# CPU_ETM register map
Vendor: Texas Instruments
Peripheral module from a debugger description file (folder CC26x4).
Registers are 32-bit, access per field, reset 0x0 unless marked. A register's access mark holds for its fields unless they carry their own. Offsets are as the file gives them; lines under a group give offsets from that group; [hi:lo] are bit positions; {n}, {i} and the like mark numbered series; 'fields as' and 'values as' point back to an identical list; <NAME> marks a mode.

## CPU_ETM
0x04 TRCPRGCTLR — Programming Control Register
  [0] EN rw — Trace Unit Enable
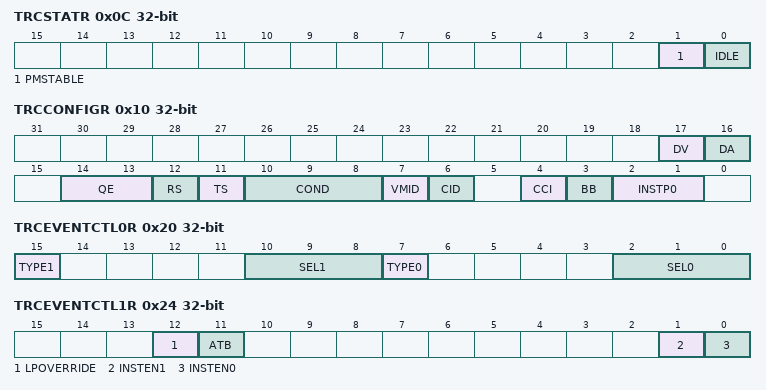
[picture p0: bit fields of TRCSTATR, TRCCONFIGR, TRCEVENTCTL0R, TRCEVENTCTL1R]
0x0C TRCSTATR ro — The TRCSTATR indicates the ETM-Teal status
  [1] PMSTABLE — Indicates whether the ETM-Teal registers are stable and can be read
  [0] IDLE — Indicates that the trace unit is inactive
0x10 TRCCONFIGR ro — The TRCCONFIGR sets the basic tracing options for the trace unit
  [17] DV — Reserved, `ImpDefRES0
  [16] DA — Reserved, `ImpDefRES0
  [14:13] QE — Reserved, `ImpDefRES0
  [12] RS — Reserved, `ImpDefRES0
  [11] TS — Reserved, `ImpDefRES0
  [10:8] COND — Reserved, `ImpDefRES0
  [7] VMID — Reserved, `ImpDefRES0
  [6] CID — Reserved, `ImpDefRES0
  [4] CCI — Reserved, `ImpDefRES0
  [3] BB — Reserved, `ImpDefRES0
  [2:1] INSTP0 — Reserved, `ImpDefRES0
0x20 TRCEVENTCTL0R — The TRCEVENTCTL0R controls the tracing of events in the trace stream. The events also drive the ETM-Teal external outputs.
  [15] TYPE1 rw — Selects the resource type for event 1
  [10:8] SEL1 rw — Selects the resource number, based on the value of TYPE1: When TYPE1 is 0, selects a single selected resource from 0-15 defined by SEL1[2:0]. When TYPE1 is 1, selects a Boolean combined resource pair from 0-7 defined by SEL1[2:0]
  [7] TYPE0 rw — Selects the resource type for event 0
  [2:0] SEL0 rw — Selects the resource number, based on the value of TYPE0: When TYPE1 is 0, selects a single selected resource from 0-15 defined by SEL0[2:0]. When TYPE1 is 1, selects a Boolean combined resource pair from 0-7 defined by SEL0[2:0]
0x24 TRCEVENTCTL1R — The TRCEVENTCTL1R controls how the events selected by TRCEVENTCTL0R behave
  [12] LPOVERRIDE rw — Low power state behavior override
  [11] ATB rw — ATB enabled
  [1] INSTEN1 rw — One bit per event, to enable generation of an event element in the instruction trace stream when the selected event occurs
  [0] INSTEN0 rw — One bit per event, to enable generation of an event element in the instruction trace stream when the selected event occurs
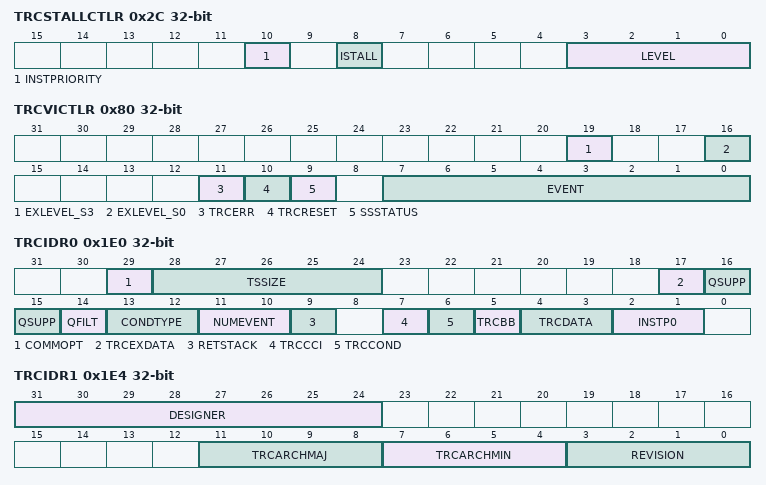
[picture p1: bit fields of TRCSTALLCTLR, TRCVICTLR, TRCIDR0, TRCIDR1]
0x2C TRCSTALLCTLR — The TRCSTALLCTLR enables ETM-Teal to stall the processor if the ETM-Teal FIFO goes over the programmed level to minimize risk of overflow
  [10] INSTPRIORITY rw — Prioritize instruction trace if instruction trace buffer space is less than LEVEL
  [8] ISTALL rw — Stall processor based on instruction trace buffer space
  [3:0] LEVEL rw — Threshold at which stalling becomes active. This provides four levels. This level can be varied to optimize the level of invasion caused by stalling, balanced against the risk of a FIFO overflow
0x30 TRCTSCTLR — The TRCTSCTLR controls the insertion of global timestamps into the trace stream. A timestamp is always inserted into the instruction trace stream
  [7:0] EVENT rw — An event selector. When the selected event is triggered, the trace unit inserts a global timestamp into the trace streams
0x34 TRCSYNCPR ro — The TRCSYNCPR specifies the period of trace synchronization of the trace streams. TRCSYNCPR defines a number of bytes of trace between requests for trace synchronization. This value is always a power of two
  [4:0] PERIOD — Defines the number of bytes of trace between trace synchronization requests as a total of the number of bytes generated by the instruction stream. The number of bytes is 2N where N is the value of this field: - A value of zero disables these periodic trace synchronization requests, but does not disable other trace synchronization requests. - The minimum value that can be programmed, other than zero, is 8, providing a minimum trace synchronization period of 256 bytes. - The maximum value is 20, providing a maximum trace synchronization period of 2^20 bytes
0x38 TRCCCCTLR — The TRCCCCTLR sets the threshold value for instruction trace cycle counting. The threshold represents the minimum interval between cycle count trace packets
  [11:0] THRESHOLD rw — Instruction trace cycle count threshold
0x80 TRCVICTLR — The TRCVICTLR controls instruction trace filtering
  [19] EXLEVEL_S3 rw — In Secure state, each bit controls whether instruction tracing is enabled for the corresponding exception level
  [16] EXLEVEL_S0 rw — In Secure state, each bit controls whether instruction tracing is enabled for the corresponding exception level
  [11] TRCERR rw — Selects whether a system error exception must always be traced
  [10] TRCRESET rw — Selects whether a reset exception must always be traced
  [9] SSSTATUS rw — Indicates the current status of the start/stop logic
  [7:0] EVENT rw — An event selector
{0x140+4i} TRCCNTRLDVR{i} (i=0..2) — The TRCCNTRLDVR defines the reload value for the reduced function counter
  [15:0] VALUE rw — Defines the reload value for the counter. This value is loaded into the counter each time the reload event occurs
0x180 TRCIDR8 ro
  [31:0] MAXSPEC — reads as `ImpDef
0x184 TRCIDR9 ro
  [31:0] NUMP0KEY — reads as `ImpDef
0x188 TRCIDR10 ro
  [31:0] NUMP1KEY — reads as `ImpDef
0x18C TRCIDR11 ro
  [31:0] NUMP1SPC — reads as `ImpDef
0x190 TRCIDR12 ro
  [31:0] NUMCONDKEY — reads as `ImpDef
0x194 TRCIDR13 ro
  [31:0] NUMCONDSPC — reads as `ImpDef
{0x1C0+4i} TRCIMSPEC{i} (i=0..6) — The TRCIMSPEC shows the presence of any IMPLEMENTATION SPECIFIC features, and enables any features that are provided
  [3:0] SUPPORT rw — Set to 0. No IMPLEMENTATION SPECIFIC extensions are supported
0x1E0 TRCIDR0 ro
  [29] COMMOPT — reads as `ImpDef
  [28:24] TSSIZE — reads as `ImpDef
  [17] TRCEXDATA — reads as `ImpDef
  [16:15] QSUPP — reads as `ImpDef
  [14] QFILT — reads as `ImpDef
  [13:12] CONDTYPE — reads as `ImpDef
  [11:10] NUMEVENT — reads as `ImpDef
  [9] RETSTACK — reads as `ImpDef
  [7] TRCCCI — reads as `ImpDef
  [6] TRCCOND — reads as `ImpDef
  [5] TRCBB — reads as `ImpDef
  [4:3] TRCDATA — reads as `ImpDef
  [2:1] INSTP0 — reads as `ImpDef
0x1E4 TRCIDR1 ro
  [31:24] DESIGNER — reads as `ImpDef
  [11:8] TRCARCHMAJ — reads as 0b0100
  [7:4] TRCARCHMIN — reads as 0b0000
  [3:0] REVISION — reads as `ImpDef
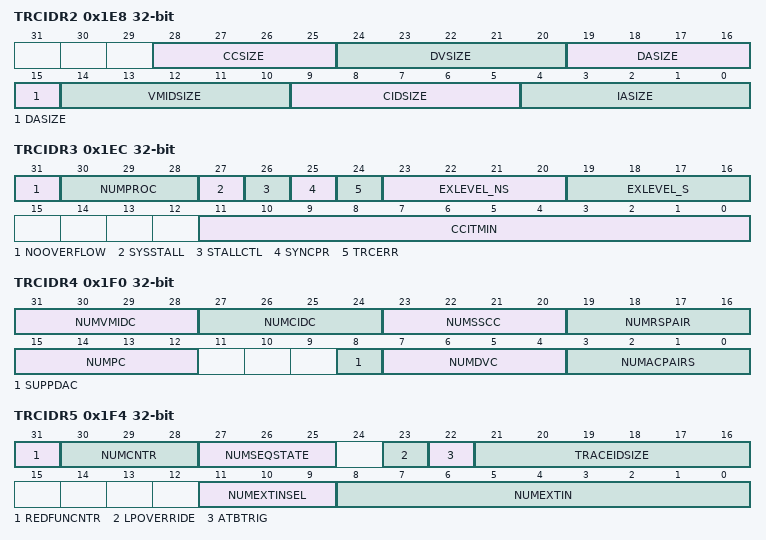
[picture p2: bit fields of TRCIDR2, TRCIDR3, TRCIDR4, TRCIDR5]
0x1E8 TRCIDR2 ro
  [28:25] CCSIZE — reads as `ImpDef
  [24:20] DVSIZE — reads as `ImpDef
  [19:15] DASIZE — reads as `ImpDef
  [14:10] VMIDSIZE — reads as `ImpDef
  [9:5] CIDSIZE — reads as `ImpDef
  [4:0] IASIZE — reads as `ImpDef
0x1EC TRCIDR3 ro
  [31] NOOVERFLOW — reads as `ImpDef
  [30:28] NUMPROC — reads as `ImpDef
  [27] SYSSTALL — reads as `ImpDef
  [26] STALLCTL — reads as `ImpDef
  [25] SYNCPR — reads as `ImpDef
  [24] TRCERR — reads as `ImpDef
  [23:20] EXLEVEL_NS — reads as `ImpDef
  [19:16] EXLEVEL_S — reads as `ImpDef
  [11:0] CCITMIN — reads as `ImpDef
0x1F0 TRCIDR4 ro
  [31:28] NUMVMIDC — reads as `ImpDef
  [27:24] NUMCIDC — reads as `ImpDef
  [23:20] NUMSSCC — reads as `ImpDef
  [19:16] NUMRSPAIR — reads as `ImpDef
  [15:12] NUMPC — reads as `ImpDef
  [8] SUPPDAC — reads as `ImpDef
  [7:4] NUMDVC — reads as `ImpDef
  [3:0] NUMACPAIRS — reads as `ImpDef
0x1F4 TRCIDR5 ro
  [31] REDFUNCNTR — reads as `ImpDef
  [30:28] NUMCNTR — reads as `ImpDef
  [27:25] NUMSEQSTATE — reads as `ImpDef
  [23] LPOVERRIDE — reads as `ImpDef
  [22] ATBTRIG — reads as `ImpDef
  [21:16] TRACEIDSIZE — reads as 0x07
  [11:9] NUMEXTINSEL — reads as `ImpDef
  [8:0] NUMEXTIN — reads as `ImpDef
0x1F8 TRCIDR6 ro
0x1FC TRCIDR7 ro
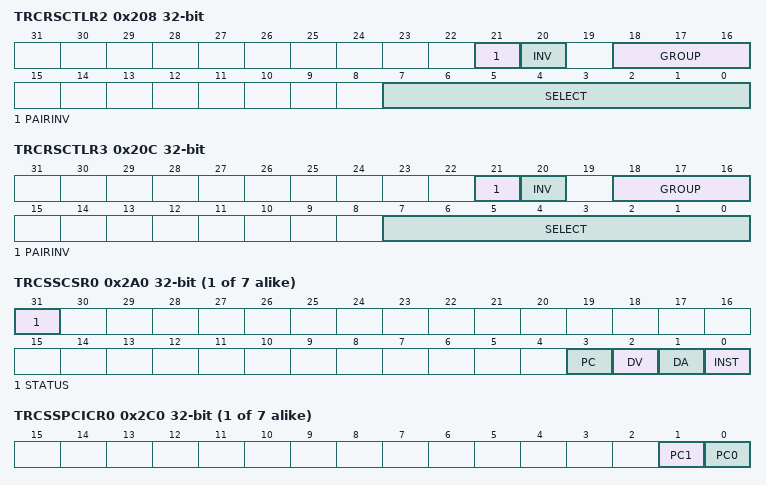
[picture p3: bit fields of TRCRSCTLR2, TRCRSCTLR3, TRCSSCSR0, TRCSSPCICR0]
0x208 TRCRSCTLR2 — The TRCRSCTLR controls the trace resources
  [21] PAIRINV rw — Inverts the result of a combined pair of resources. This bit is only implemented on the lower register for a pair of resource selectors
  [20] INV rw — Inverts the selected resources
  [18:16] GROUP rw — Selects a group of resource
  [7:0] SELECT rw — Selects one or more resources from the wanted group. One bit is provided per resource from the group
0x20C TRCRSCTLR3 — The TRCRSCTLR controls the trace resources
  fields as TRCRSCTLR2
{0x2A0+4i} TRCSSCSR{i} (i=0..6) — Controls the corresponding single-shot comparator resource
  [31] STATUS rw — Single-shot status bit. Indicates if any of the comparators, that TRCSSCCRn.SAC or TRCSSCCRn.ARC selects, have matched
  [3] PC rw — PE comparator input support. Indicates if the trace unit supports Single-shot PE comparator inputs. This field is read-only
  [2] DV rw — Data value comparator support bit. Indicates if the trace unit supports data address with data value comparisons. This field is read-only:
  [1] DA rw — Data address comparator support bit. Indicates if the trace unit supports data address comparisons. This field is read-only:
  [0] INST rw — Instruction address comparator support bit. Indicates if the trace unit supports instruction address comparisons. This field is read-only:
{0x2C0+4i} TRCSSPCICR{i} (i=0..6) — Selects the PE comparator inputs for Single-shot control
  [1] PC1 rw — Selects one or more PE comparator inputs for Single-shot control. TRCIDR4.NUMPC defines the size of the PC field. 1 bit is provided for each implemented PE comparator input. For example, if bit[1] == 1 this selects PE comparator input 1 for Single-shot control
  [0] PC0 rw — Selects one or more PE comparator inputs for Single-shot control. TRCIDR4.NUMPC defines the size of the PC field. 1 bit is provided for each implemented PE comparator input. For example, if bit[1] == 1 this selects PE comparator input 1 for Single-shot control
0x310 TRCPDCR — Requests the system to provide power to the trace unit
  [3] PU rw — Powerup request bit:
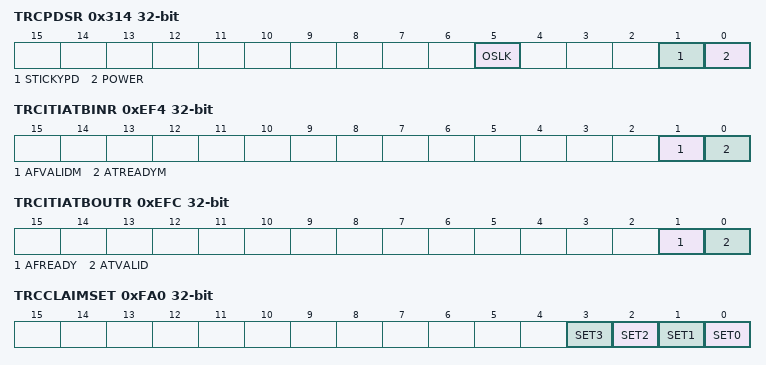
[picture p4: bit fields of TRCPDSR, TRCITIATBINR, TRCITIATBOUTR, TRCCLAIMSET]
0x314 TRCPDSR ro — Returns the following information about the trace unit: - OS Lock status. - Core power domain status. - Power interruption status
  [5] OSLK — OS Lock status bit:
  [1] STICKYPD — Sticky powerdown status bit. Indicates whether the trace register state is valid:
  [0] POWER — Power status bit:
0xEE4 TRCITATBIDR — Trace Intergration ATB Identification Register
  [6:0] ID rw — Trace ID
0xEF4 TRCITIATBINR — Trace Integration Instruction ATB In Register
  [1] AFVALIDM rw — Integration Mode instruction AFVALIDM in
  [0] ATREADYM rw — Integration Mode instruction ATREADYM in
0xEFC TRCITIATBOUTR — Trace Integration Instruction ATB Out Register
  [1] AFREADY rw — Integration Mode instruction AFREADY out
  [0] ATVALID rw — Integration Mode instruction ATVALID out
0xFA0 TRCCLAIMSET — Claim Tag Set Register
  [n] SET{n} rw (n=0..3) — When a write to one of these bits occurs, with the value:
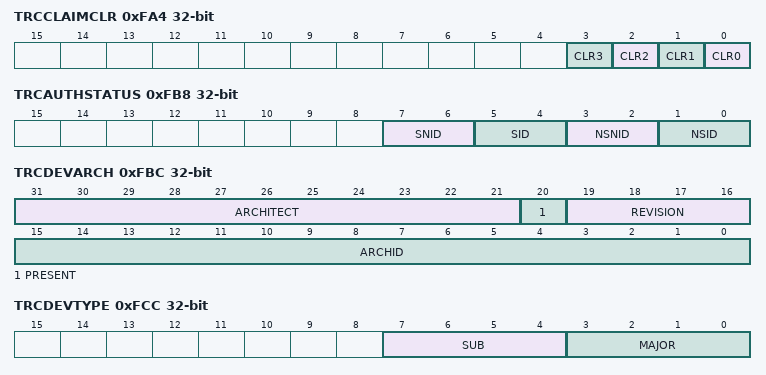
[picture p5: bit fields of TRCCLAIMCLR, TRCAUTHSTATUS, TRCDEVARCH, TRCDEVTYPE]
0xFA4 TRCCLAIMCLR — Claim Tag Clear Register
  [n] CLR{n} rw (n=0..3) — When a write to one of these bits occurs, with the value:
0xFB8 TRCAUTHSTATUS ro — Returns the level of tracing that the trace unit can support
  [7:6] SNID — Indicates whether the system enables the trace unit to support Secure non-invasive debug:
  [5:4] SID — Indicates whether the trace unit supports Secure invasive debug:
  [3:2] NSNID — Indicates whether the system enables the trace unit to support Non-secure non-invasive debug:
  [1:0] NSID — Indicates whether the trace unit supports Non-secure invasive debug:
0xFBC TRCDEVARCH ro
  [31:21] ARCHITECT — reads as 0b01000111011
  [20] PRESENT — reads as 0b1
  [19:16] REVISION — reads as 0b0000
  [15:0] ARCHID — reads as 0b0100101000010011
0xFC8 TRCDEVID ro
0xFCC TRCDEVTYPE ro
  [7:4] SUB — reads as 0b0001
  [3:0] MAJOR — reads as 0b0011
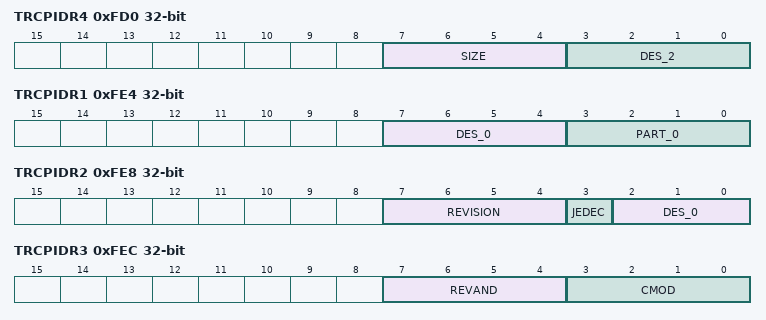
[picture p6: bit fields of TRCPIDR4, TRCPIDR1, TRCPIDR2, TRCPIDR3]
0xFD0 TRCPIDR4 ro
  [7:4] SIZE — reads as `ImpDef
  [3:0] DES_2 — reads as `ImpDef
{0xFC0+4i} TRCPIDR{i} ro (i=5..7)
0xFE0 TRCPIDR0 ro
  [7:0] PART_0 — reads as `ImpDef
0xFE4 TRCPIDR1 ro
  [7:4] DES_0 — reads as `ImpDef
  [3:0] PART_0 — reads as `ImpDef
0xFE8 TRCPIDR2 ro
  [7:4] REVISION — reads as `ImpDef
  [3] JEDEC — reads as 0b1
  [2:0] DES_0 — reads as `ImpDef
0xFEC TRCPIDR3 ro
  [7:4] REVAND — reads as `ImpDef
  [3:0] CMOD — reads as `ImpDef
0xFF0 TRCCIDR0 ro
  [7:0] PRMBL_0 — reads as 0b00001101
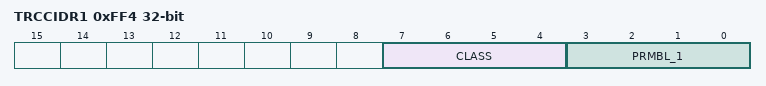
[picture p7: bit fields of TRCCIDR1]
0xFF4 TRCCIDR1 ro
  [7:4] CLASS — reads as 0b1001
  [3:0] PRMBL_1 — reads as 0b0000
0xFF8 TRCCIDR2 ro
  [7:0] PRMBL_2 — reads as 0b00000101
0xFFC TRCCIDR3 ro
  [7:0] PRMBL_3 — reads as 0b10110001
